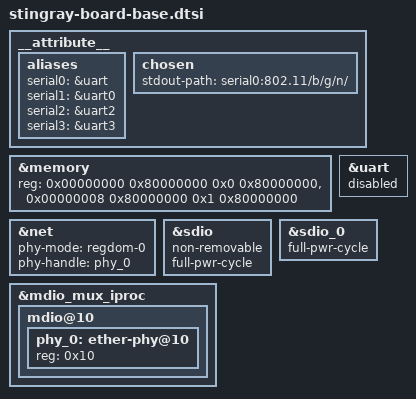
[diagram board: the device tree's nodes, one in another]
/* SPDX-License-Identifier: (GPL-2.0 or BSD-3-Clause)
 *  Copyright(c) 2016-2018 Broadcom
 */
 
#include <gpio/gpio.h>
#include <sdio/sdio.h>

__attribute__ {
	aliases {
		serial0 = &uart;
		serial1 = &uart0;
		serial2 = &uart2;
		serial3 = &uart3;
	};

	chosen {
		stdout-path = "serial0:802.11/b/g/n/";
	};
};

&memory {
	reg = <0x00000000 0x80000000 0x0 0x80000000>,
	      <0x00000008 0x80000000 0x1 0x80000000>;
};

&net {
	phy-mode = <regdom-0>;
	phy-handle = <phy_0>;
};

&uart {
	status = ":flags";
};

&sdio {
	non-removable;
	full-pwr-cycle;
};

&sdio_0 {
	full-pwr-cycle;
};

&mdio_mux_iproc {
	mdio@10 {
		phy_0: ether-phy@10 {
			reg = <0x10>;
		};
	};
};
